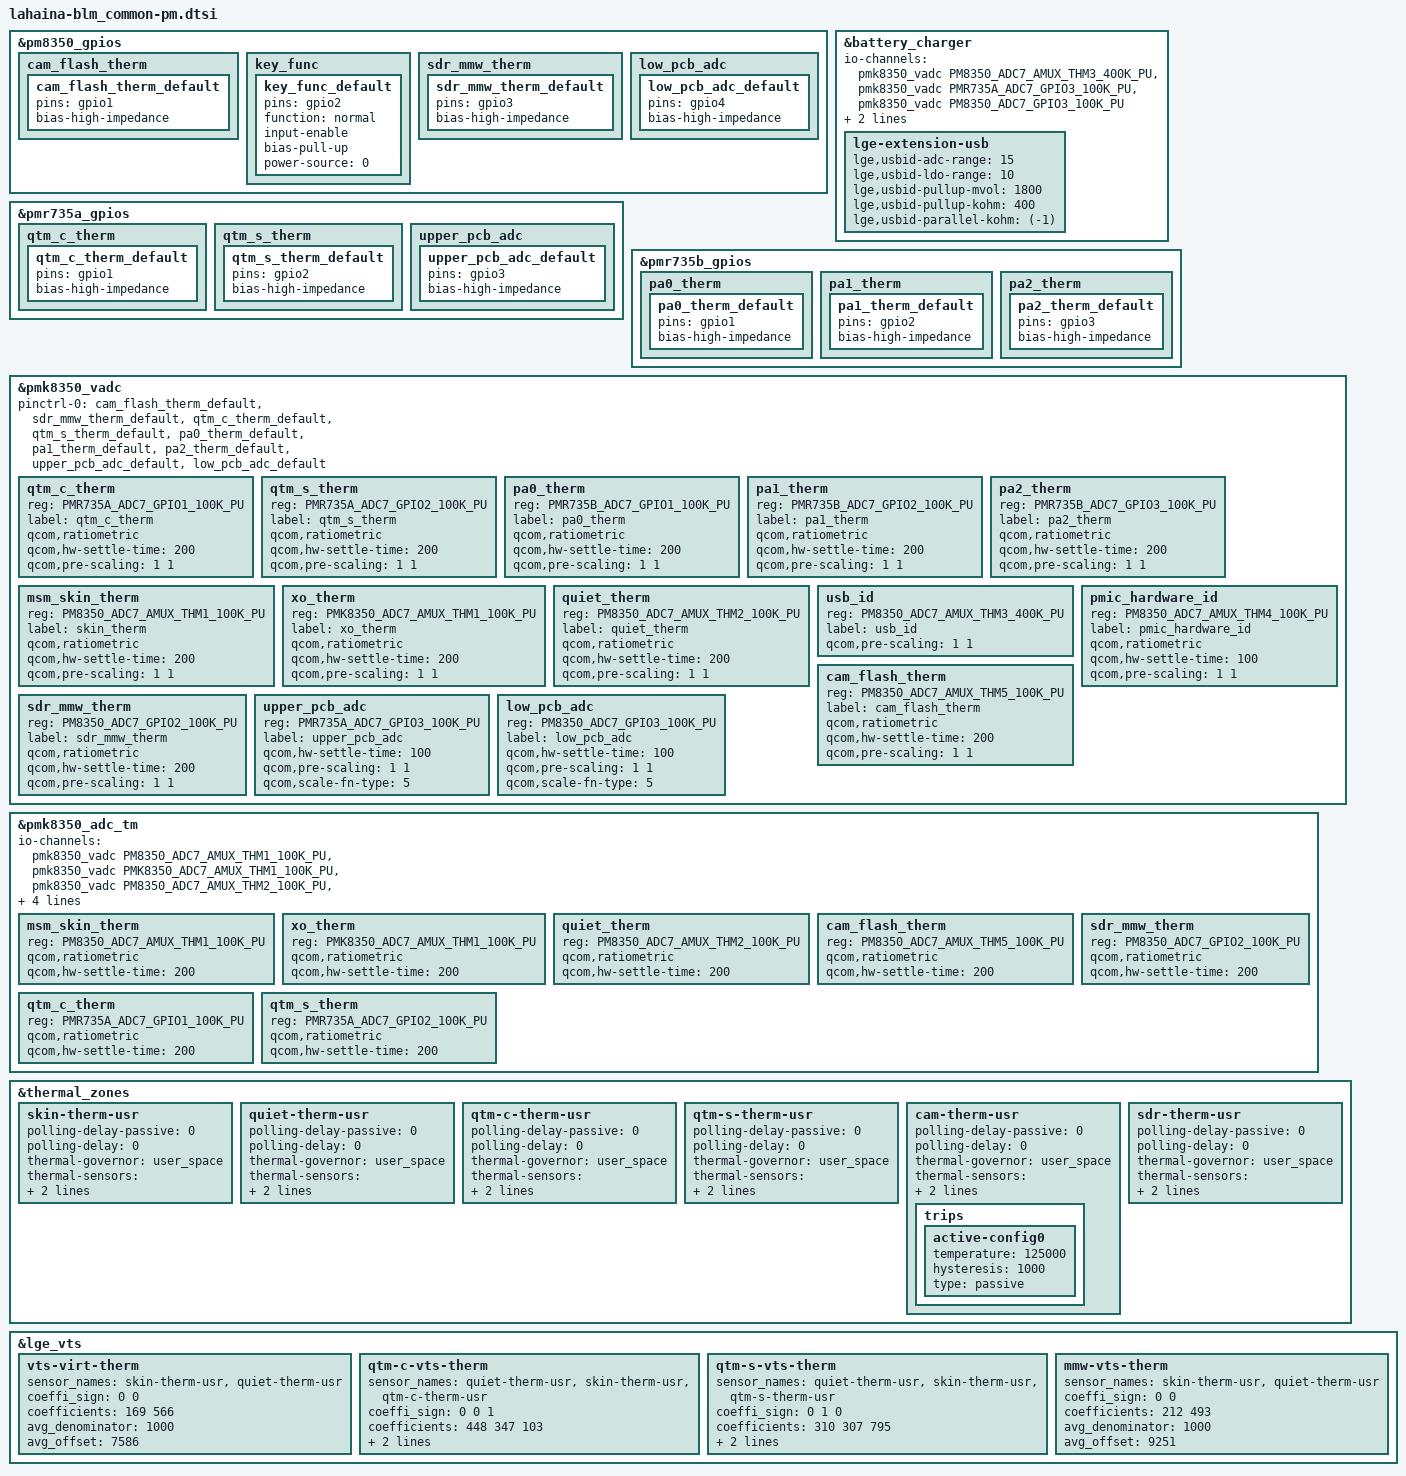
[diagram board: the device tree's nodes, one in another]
#include "../../lahaina_common/lahaina_common-pm.dtsi"
#include "../../lahaina_common/lahaina_common-veneer.dtsi"
#include "lahaina-blm_common-veneer.dtsi"


&pm8350_gpios {
	cam_flash_therm {
		cam_flash_therm_default: cam_flash_therm_default {
			pins = "gpio1";
			bias-high-impedance;
		};
	};
    	key_func {
    		key_func_default: key_func_default {
			pins = "gpio2";
			function = "normal";
			input-enable;
			bias-pull-up;
			power-source = <0>;
		};
        };
	sdr_mmw_therm {
		sdr_mmw_therm_default: sdr_mmw_therm_default {
			pins = "gpio3";
			bias-high-impedance;
		};
	};
	low_pcb_adc {
		low_pcb_adc_default: low_pcb_adc_default {
			pins = "gpio4";
			bias-high-impedance;
		};
	};
};

&battery_charger {
	io-channels = <&pmk8350_vadc PM8350_ADC7_AMUX_THM3_400K_PU>,
			<&pmk8350_vadc PMR735A_ADC7_GPIO3_100K_PU>,
			<&pmk8350_vadc PM8350_ADC7_GPIO3_100K_PU>;
	io-channel-names = "usb_id",
			"upper_pcb_adc",
			"low_pcb_adc";

	/delete-property/ qcom,thermal-mitigation;

	lge,hvdcp-disable-jp;
	lge,pcb-battery-id = <390000>;
	lge-extension-usb {
		lge,usbid-adc-range = <15>;		// ADC margin (pct unit)
		lge,usbid-ldo-range = <10>;		// LDO margin (pct unit)
		lge,usbid-pullup-mvol = <1800>;		// Pull-up voltage
		lge,usbid-pullup-kohm = <400>;		// Pull-up resistance
		lge,usbid-parallel-kohm = <(-1)>;	// Pull-up resistance
	};
};

&pmr735a_gpios {
	qtm_c_therm {
		qtm_c_therm_default: qtm_c_therm_default {
			pins = "gpio1";
			bias-high-impedance;
		};
	};

	qtm_s_therm {
		qtm_s_therm_default: qtm_s_therm_default {
			pins = "gpio2";
			bias-high-impedance;
		};
	};

	upper_pcb_adc {
		upper_pcb_adc_default: upper_pcb_adc_default {
			pins = "gpio3";
			bias-high-impedance;
		};
	};
};

&pmr735b_gpios {
	pa0_therm {
		pa0_therm_default: pa0_therm_default {
			pins = "gpio1";
			bias-high-impedance;
		};
	};

	pa1_therm {
		pa1_therm_default: pa1_therm_default {
			pins = "gpio2";
			bias-high-impedance;
		};
	};

	pa2_therm {
		pa2_therm_default: pa2_therm_default {
			pins = "gpio3";
			bias-high-impedance;
		};
	};
};

&pmk8350_vadc {
	pinctrl-names = "default";
	pinctrl-0 = <&cam_flash_therm_default
		&sdr_mmw_therm_default
		&qtm_c_therm_default
		&qtm_s_therm_default
		&pa0_therm_default
		&pa1_therm_default
		&pa2_therm_default
		&upper_pcb_adc_default
		&low_pcb_adc_default>;

	qtm_c_therm {
		reg = <PMR735A_ADC7_GPIO1_100K_PU>;
		label = "qtm_c_therm";
		qcom,ratiometric;
		qcom,hw-settle-time = <200>;
		qcom,pre-scaling = <1 1>;
	};

	qtm_s_therm {
		reg = <PMR735A_ADC7_GPIO2_100K_PU>;
		label = "qtm_s_therm";
		qcom,ratiometric;
		qcom,hw-settle-time = <200>;
		qcom,pre-scaling = <1 1>;
	};

	pa0_therm {
		reg = <PMR735B_ADC7_GPIO1_100K_PU>;
		label = "pa0_therm";
		qcom,ratiometric;
		qcom,hw-settle-time = <200>;
		qcom,pre-scaling = <1 1>;
	};

	pa1_therm {
		reg = <PMR735B_ADC7_GPIO2_100K_PU>;
		label = "pa1_therm";
		qcom,ratiometric;
		qcom,hw-settle-time = <200>;
		qcom,pre-scaling = <1 1>;
	};

	pa2_therm {
		reg = <PMR735B_ADC7_GPIO3_100K_PU>;
		label = "pa2_therm";
		qcom,ratiometric;
		qcom,hw-settle-time = <200>;
		qcom,pre-scaling = <1 1>;
	};

	msm_skin_therm {
		reg = <PM8350_ADC7_AMUX_THM1_100K_PU>;
		label = "skin_therm";
		qcom,ratiometric;
		qcom,hw-settle-time = <200>;
		qcom,pre-scaling = <1 1>;
	};

	xo_therm {
		reg = <PMK8350_ADC7_AMUX_THM1_100K_PU>;
		label = "xo_therm";
		qcom,ratiometric;
		qcom,hw-settle-time = <200>;
		qcom,pre-scaling = <1 1>;
	};

	quiet_therm {
		reg = <PM8350_ADC7_AMUX_THM2_100K_PU>;
		label = "quiet_therm";
		qcom,ratiometric;
		qcom,hw-settle-time = <200>;
		qcom,pre-scaling = <1 1>;
	};

	usb_id {
		reg = <PM8350_ADC7_AMUX_THM3_400K_PU>;
		label = "usb_id";
		qcom,pre-scaling = <1 1>;
	};

	pmic_hardware_id {
		reg = <PM8350_ADC7_AMUX_THM4_100K_PU>;
		label = "pmic_hardware_id";
		qcom,ratiometric;
		qcom,hw-settle-time = <100>;
		qcom,pre-scaling = <1 1>;
	};

	cam_flash_therm {
		reg = <PM8350_ADC7_AMUX_THM5_100K_PU>;
		label = "cam_flash_therm";
		qcom,ratiometric;
		qcom,hw-settle-time = <200>;
		qcom,pre-scaling = <1 1>;
	};

	sdr_mmw_therm {
		reg = <PM8350_ADC7_GPIO2_100K_PU>;
		label = "sdr_mmw_therm";
		qcom,ratiometric;
		qcom,hw-settle-time = <200>;
		qcom,pre-scaling = <1 1>;
	};

	upper_pcb_adc {
		reg = <PMR735A_ADC7_GPIO3_100K_PU>;
		label = "upper_pcb_adc";
		qcom,hw-settle-time = <100>;
		qcom,pre-scaling = <1 1>;
		qcom,scale-fn-type = <5>;
	};

	low_pcb_adc {
		reg = <PM8350_ADC7_GPIO3_100K_PU>;
		label = "low_pcb_adc";
		qcom,hw-settle-time = <100>;
		qcom,pre-scaling = <1 1>;
		qcom,scale-fn-type = <5>;
	};
};

&pmk8350_adc_tm {
	io-channels = <&pmk8350_vadc PM8350_ADC7_AMUX_THM1_100K_PU>,
		<&pmk8350_vadc PMK8350_ADC7_AMUX_THM1_100K_PU>,
		<&pmk8350_vadc PM8350_ADC7_AMUX_THM2_100K_PU>,
		<&pmk8350_vadc PM8350_ADC7_AMUX_THM5_100K_PU>,
		<&pmk8350_vadc PM8350_ADC7_GPIO2_100K_PU>,
		<&pmk8350_vadc PMR735A_ADC7_GPIO1_100K_PU>,
		<&pmk8350_vadc PMR735A_ADC7_GPIO2_100K_PU>;

	msm_skin_therm {
		reg = <PM8350_ADC7_AMUX_THM1_100K_PU>;
		qcom,ratiometric;
		qcom,hw-settle-time = <200>;
	};

	xo_therm {
		reg = <PMK8350_ADC7_AMUX_THM1_100K_PU>;
		qcom,ratiometric;
		qcom,hw-settle-time = <200>;
	};

	quiet_therm {
		reg = <PM8350_ADC7_AMUX_THM2_100K_PU>;
		qcom,ratiometric;
		qcom,hw-settle-time = <200>;
	};

	cam_flash_therm {
		reg = <PM8350_ADC7_AMUX_THM5_100K_PU>;
		qcom,ratiometric;
		qcom,hw-settle-time = <200>;
	};

	sdr_mmw_therm {
		reg = <PM8350_ADC7_GPIO2_100K_PU>;
		qcom,ratiometric;
		qcom,hw-settle-time = <200>;
	};

	qtm_c_therm {
		reg = <PMR735A_ADC7_GPIO1_100K_PU>;
		qcom,ratiometric;
		qcom,hw-settle-time = <200>;
	};

	qtm_s_therm {
		reg = <PMR735A_ADC7_GPIO2_100K_PU>;
		qcom,ratiometric;
		qcom,hw-settle-time = <200>;
	};
};

&thermal_zones {
	skin-therm-usr {
		polling-delay-passive = <0>;
		polling-delay = <0>;
		thermal-governor = "user_space";
		thermal-sensors = <&pmk8350_adc_tm PM8350_ADC7_AMUX_THM1_100K_PU>;
		wake-capable-sensor;
	};

	quiet-therm-usr {
		polling-delay-passive = <0>;
		polling-delay = <0>;
		thermal-governor = "user_space";
		thermal-sensors = <&pmk8350_adc_tm PM8350_ADC7_AMUX_THM2_100K_PU>;
		wake-capable-sensor;
	};

	qtm-c-therm-usr {
		polling-delay-passive = <0>;
		polling-delay = <0>;
		thermal-governor = "user_space";
		thermal-sensors = <&pmk8350_adc_tm PMR735A_ADC7_GPIO1_100K_PU>;
		wake-capable-sensor;
	};

	qtm-s-therm-usr {
		polling-delay-passive = <0>;
		polling-delay = <0>;
		thermal-governor = "user_space";
		thermal-sensors = <&pmk8350_adc_tm PMR735A_ADC7_GPIO2_100K_PU>;
		wake-capable-sensor;
	};

	cam-therm-usr {
		polling-delay-passive = <0>;
		polling-delay = <0>;
		thermal-governor = "user_space";
		thermal-sensors = <&pmk8350_adc_tm PM8350_ADC7_AMUX_THM5_100K_PU>;
		wake-capable-sensor;
		trips {
			active-config0 {
				temperature = <125000>;
				hysteresis = <1000>;
				type = "passive";
			};
		};
	};

	sdr-therm-usr {
		polling-delay-passive = <0>;
		polling-delay = <0>;
		thermal-governor = "user_space";
		thermal-sensors = <&pmk8350_adc_tm PM8350_ADC7_GPIO2_100K_PU>;
		wake-capable-sensor;
	};
};

&lge_vts {
	vts-virt-therm {
		sensor_names = "skin-therm-usr", "quiet-therm-usr";
		coeffi_sign = <0 0>;
		coefficients = <169 566>;
		avg_denominator = <1000>;
		avg_offset = <7586>;
	};
	qtm-c-vts-therm {
		sensor_names = "quiet-therm-usr", "skin-therm-usr", "qtm-c-therm-usr";
		coeffi_sign = <0 0 1>;
		coefficients = <448 347 103>;
		avg_denominator = <1000>;
		avg_offset = <9470>;
	};
	qtm-s-vts-therm {
		sensor_names = "quiet-therm-usr", "skin-therm-usr", "qtm-s-therm-usr";
		coeffi_sign = <0 1 0>;
		coefficients = <310 307 795>;
		avg_denominator = <1000>;
		avg_offset = <4942>;
	};
	mmw-vts-therm {
		sensor_names = "skin-therm-usr", "quiet-therm-usr";
		coeffi_sign = <0 0>;
		coefficients = <212 493>;
		avg_denominator = <1000>;
		avg_offset = <9251>;
	};
};
